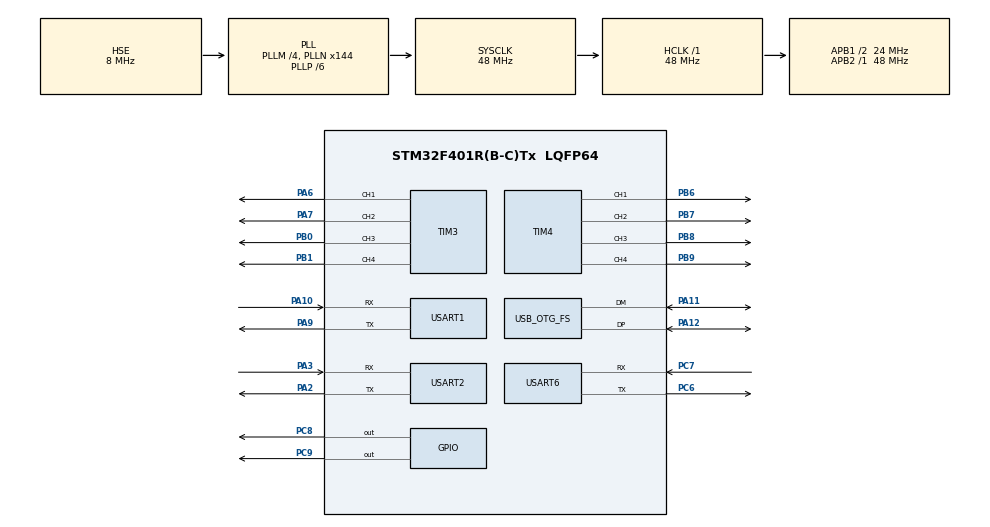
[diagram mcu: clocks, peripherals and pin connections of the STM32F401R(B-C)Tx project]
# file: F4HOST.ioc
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Mcu.Family=STM32F4
Mcu.Name=STM32F401R(B-C)Tx
Mcu.Package=LQFP64
NVIC.OTG_FS_IRQn=true\:0\:0\:false\:false\:true\:false\:true\:true
NVIC.PriorityGroup=NVIC_PRIORITYGROUP_4
PA10.Mode=Asynchronous
PA10.Signal=USART1_RX
PA11.Mode=Host_Only
PA11.Signal=USB_OTG_FS_DM
PA12.Mode=Host_Only
PA12.Signal=USB_OTG_FS_DP
PA13.Mode=Serial_Wire
PA13.Signal=SYS_JTMS-SWDIO
PA14.Mode=Serial_Wire
PA14.Signal=SYS_JTCK-SWCLK
PA2.Mode=Asynchronous
PA2.Signal=USART2_TX
PA3.Mode=Asynchronous
PA3.Signal=USART2_RX
PA6.Signal=S_TIM3_CH1
PA7.Signal=S_TIM3_CH2
PA9.Mode=Asynchronous
PA9.Signal=USART1_TX
PB0.Signal=S_TIM3_CH3
PB1.Signal=S_TIM3_CH4
PB6.Signal=S_TIM4_CH1
PB7.Signal=S_TIM4_CH2
PB8.Signal=S_TIM4_CH3
PB9.Signal=S_TIM4_CH4
PC6.Mode=Asynchronous
PC6.Signal=USART6_TX
PC7.Mode=Asynchronous
PC7.Signal=USART6_RX
PC8.Signal=GPIO_Output
PC9.Signal=GPIO_Output
PH0\ -\ OSC_IN.Mode=HSE-External-Oscillator
PH0\ -\ OSC_IN.Signal=RCC_OSC_IN
PH1\ -\ OSC_OUT.Mode=HSE-External-Oscillator
PH1\ -\ OSC_OUT.Signal=RCC_OSC_OUT
ProjectManager.HeapSize=0x400
ProjectManager.StackSize=0x800
ProjectManager.TargetToolchain=MDK-ARM V5.32
RCC.48MHZClocksFreq_Value=48000000
RCC.AHBFreq_Value=48000000
RCC.APB1CLKDivider=RCC_HCLK_DIV2
RCC.APB1Freq_Value=24000000
RCC.APB1TimFreq_Value=48000000
RCC.APB2Freq_Value=48000000
RCC.APB2TimFreq_Value=48000000
RCC.CortexFreq_Value=48000000
RCC.HCLKFreq_Value=48000000
RCC.HSE_VALUE=8000000
RCC.HSICalibrationValue=8
RCC.HSI_VALUE=16000000
RCC.LSE_VALUE=32768
RCC.PLLM=4
RCC.PLLN=144
RCC.PLLP=RCC_PLLP_DIV6
RCC.PLLQ=6
RCC.SYSCLKFreq_VALUE=48000000
RCC.SYSCLKSource=RCC_SYSCLKSOURCE_PLLCLK
RCC.VCOOutputFreq_Value=288000000
SH.S_TIM3_CH1.0=TIM3_CH1,PWM Generation1 CH1
SH.S_TIM3_CH2.0=TIM3_CH2,PWM Generation2 CH2
SH.S_TIM3_CH3.0=TIM3_CH3,PWM Generation3 CH3
SH.S_TIM3_CH4.0=TIM3_CH4,PWM Generation4 CH4
SH.S_TIM4_CH1.0=TIM4_CH1,PWM Generation1 CH1
SH.S_TIM4_CH2.0=TIM4_CH2,PWM Generation2 CH2
SH.S_TIM4_CH3.0=TIM4_CH3,PWM Generation3 CH3
SH.S_TIM4_CH4.0=TIM4_CH4,PWM Generation4 CH4
TIM3.Channel-PWM\ Generation1\ CH1=TIM_CHANNEL_1
TIM3.Channel-PWM\ Generation2\ CH2=TIM_CHANNEL_2
TIM3.Channel-PWM\ Generation3\ CH3=TIM_CHANNEL_3
TIM3.Channel-PWM\ Generation4\ CH4=TIM_CHANNEL_4
TIM4.Channel-PWM\ Generation1\ CH1=TIM_CHANNEL_1
TIM4.Channel-PWM\ Generation2\ CH2=TIM_CHANNEL_2
TIM4.Channel-PWM\ Generation3\ CH3=TIM_CHANNEL_3
TIM4.Channel-PWM\ Generation4\ CH4=TIM_CHANNEL_4
USART1.VirtualMode=VM_ASYNC
USART2.VirtualMode=VM_ASYNC
USART6.VirtualMode=VM_ASYNC
USB_HOST.SW_VBUS_DRIVE_HID_FS=true
USB_HOST.USBH_DEBUG_LEVEL=0
USB_HOST.USBH_HandleTypeDef=hUsbHostFS
USB_HOST.USBH_MAX_DATA_BUFFER=1024
USB_HOST.USBH_MAX_NUM_ENDPOINTS=4
USB_HOST.USBH_MAX_NUM_INTERFACES=8
USB_HOST.USBH_MAX_NUM_SUPPORTED_CLASS=2
USB_HOST.USBH_MAX_SIZE_CONFIGURATION=512
USB_HOST.VirtualModeFS=Hid
USB_OTG_FS.VirtualMode=Host_Only
USB_OTG_FS.phy_itface=HCD_PHY_EMBEDDED
VP_USB_HOST_VS_USB_HOST_HID_FS.Mode=HID_FS
board=custom

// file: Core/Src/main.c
/* USER CODE BEGIN Header */
/**
 ******************************************************************************
 * @file           : main.c
 * @brief          : Main program body
 ******************************************************************************
 * @attention
 *
 * Copyright (c) 2025 STMicroelectronics.
 * All rights reserved.
 *
 * This software is licensed under terms that can be found in the LICENSE file
 * in the root directory of this software component.
 * If no LICENSE file comes with this software, it is provided AS-IS.
 *
 ******************************************************************************
 */
/* USER CODE END Header */
#include "main.h"
#include "gpio.h"
#include "tim.h"
#include "usart.h"
#include "usb_host.h"

/* USER CODE BEGIN Includes */
#include "host_gamepad.h"
#include "qthezg.h"
/* USER CODE END Includes */

void SystemClock_Config(void);
void MX_USB_HOST_Process(void);

/* USER CODE BEGIN 0 */
tTimeCounterCC slider_conter_500ms = {0, 0};
tTimeCounterCC slider_conter_10ms = {0, 0};
/* USER CODE END 0 */

int main(void)
{

    /* MCU Configuration--------------------------------------------------------*/

    /* Reset of all peripherals, Initializes the Flash interface and the Systick. */
    HAL_Init();

    /* Configure the system clock */
    SystemClock_Config();

    /* Initialize all configured peripherals */
    MX_GPIO_Init();
    MX_TIM3_Init();
    MX_TIM4_Init();
    MX_USART1_UART_Init();
    MX_USART2_UART_Init();
    MX_USART6_UART_Init();
    MX_USB_HOST_Init();

    /* Infinite loop */
    /* USER CODE BEGIN WHILE */
    while (1)
    {
        INTERMITTENT_SERVICE(slider_conter_500ms, HAL_GetTick(), 500)
        {
            HAL_GPIO_TogglePin(GPIOC, GPIO_PIN_8);
        }

        INTERMITTENT_SERVICE(slider_conter_10ms, HAL_GetTick(), 10)
        {
        }

        /* USER CODE END WHILE */
        MX_USB_HOST_Process();

        /* USER CODE BEGIN 3 */
        Gamepad_AppProcess(&hUsbHostFS);
    }
    /* USER CODE END 3 */
}

void SystemClock_Config(void)
{
    RCC_OscInitTypeDef RCC_OscInitStruct = {0};
    RCC_ClkInitTypeDef RCC_ClkInitStruct = {0};

    /** Configure the main internal regulator output voltage
     */
    __HAL_RCC_PWR_CLK_ENABLE();
    __HAL_PWR_VOLTAGESCALING_CONFIG(PWR_REGULATOR_VOLTAGE_SCALE2);

    /** Initializes the RCC Oscillators according to the specified parameters
     * in the RCC_OscInitTypeDef structure.
     */
    RCC_OscInitStruct.OscillatorType = RCC_OSCILLATORTYPE_HSE;
    RCC_OscInitStruct.HSEState = RCC_HSE_ON;
    RCC_OscInitStruct.PLL.PLLState = RCC_PLL_ON;
    RCC_OscInitStruct.PLL.PLLSource = RCC_PLLSOURCE_HSE;
    RCC_OscInitStruct.PLL.PLLM = 4;
    RCC_OscInitStruct.PLL.PLLN = 144;
    RCC_OscInitStruct.PLL.PLLP = RCC_PLLP_DIV6;
    RCC_OscInitStruct.PLL.PLLQ = 6;
    if (HAL_RCC_OscConfig(&RCC_OscInitStruct) != HAL_OK)
    {
        Error_Handler();
    }

    /** Initializes the CPU, AHB and APB buses clocks
     */
    RCC_ClkInitStruct.ClockType = RCC_CLOCKTYPE_HCLK | RCC_CLOCKTYPE_SYSCLK | RCC_CLOCKTYPE_PCLK1 | RCC_CLOCKTYPE_PCLK2;
    RCC_ClkInitStruct.SYSCLKSource = RCC_SYSCLKSOURCE_PLLCLK;
    RCC_ClkInitStruct.AHBCLKDivider = RCC_SYSCLK_DIV1;
    RCC_ClkInitStruct.APB1CLKDivider = RCC_HCLK_DIV2;
    RCC_ClkInitStruct.APB2CLKDivider = RCC_HCLK_DIV1;

    if (HAL_RCC_ClockConfig(&RCC_ClkInitStruct, FLASH_LATENCY_1) != HAL_OK)
    {
        Error_Handler();
    }
}

void Error_Handler(void)
{
    __disable_irq();
    while (1)
    {
    }
}
